# ESP32 register map
Vendor: ESPRESSIF SYSTEMS (SHANGHAI) CO., LTD.; Series: ESP32 Series; File version: 17
CPU: Xtensa LX6 r0p0, little endian, no MPU, FPU, 0 interrupt priority bits
Address unit: 32 bits
Registers are 32-bit, read-write, reset 0x0 unless marked. A register's access mark holds for its fields unless they carry their own. Offsets are from the block's base; [hi:lo] are bit positions; {n}, {i} and the like mark numbered series.

## RMT — Remote Control
Base 0x3FF56000
{0x0+4i} CH{i}DATA (i=0..7) access not given
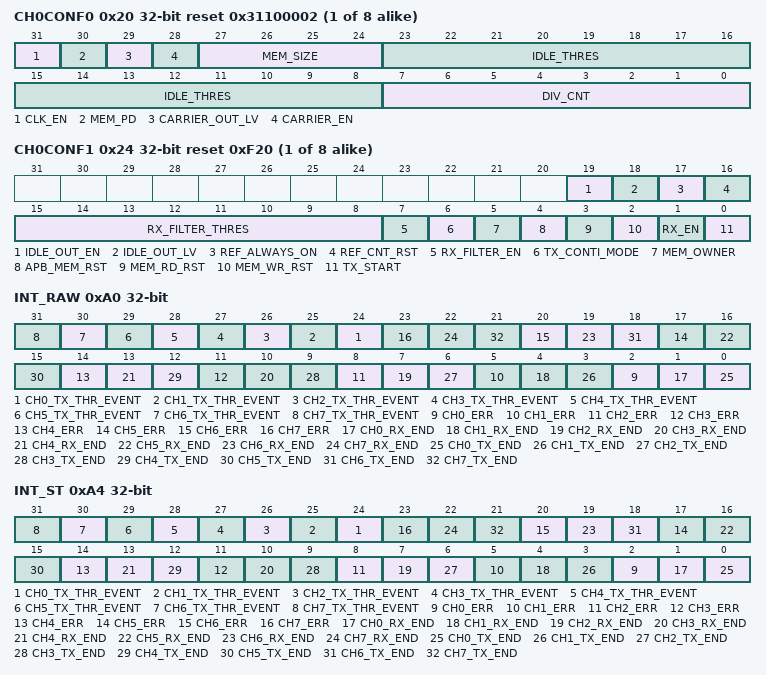
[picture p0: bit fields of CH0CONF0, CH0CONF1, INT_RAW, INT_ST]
{0x20+8i} CH{i}CONF0 (i=0..7) reset 0x31100002
  [31] CLK_EN — This bit is used to control clock.when software config RMT internal registers it controls the register clock.
  [30] MEM_PD — This bit is used to reduce power consumed by mem. 1:mem is in low power state.
  [29] CARRIER_OUT_LV — This bit is used to configure the way carrier wave is modulated for channel0.1'b1:transmit on low output level 1'b0:transmit on high output level.
  [28] CARRIER_EN — This is the carrier modulation enable control bit for channel0.
  [27:24] MEM_SIZE — This register is used to configure the the amount of memory blocks allocated to channel0.
  [23:8] IDLE_THRES — In receive mode when no edge is detected on the input signal for longer than reg_idle_thres_ch0 then the receive process is done.
  [7:0] DIV_CNT — This register is used to configure the frequency divider's factor in channel0.
{0x24+8i} CH{i}CONF1 (i=0..7) reset 0xF20
  [19] IDLE_OUT_EN — This is the output enable control bit for channel0 in IDLE state.
  [18] IDLE_OUT_LV — This bit configures the output signal's level for channel0 in IDLE state.
  [17] REF_ALWAYS_ON — This bit is used to select base clock. 1'b1:clk_apb 1'b0:clk_ref
  [16] REF_CNT_RST — This bit is used to reset divider in channel0.
  [15:8] RX_FILTER_THRES — in receive mode channel0 ignore input pulse when the pulse width is smaller then this value.
  [7] RX_FILTER_EN — This is the receive filter enable bit for channel0.
  [6] TX_CONTI_MODE — Set this bit to continue sending from the first data to the last data in channel0 again and again.
  [5] MEM_OWNER — This is the mark of channel0's ram usage right.1'b1：receiver uses the ram 0：transmitter uses the ram
  [4] APB_MEM_RST — Set this bit to reset W/R ram address for channel0 by apb fifo access
  [3] MEM_RD_RST — Set this bit to reset read ram address for channel0 by transmitter access.
  [2] MEM_WR_RST — Set this bit to reset write ram address for channel0 by receiver access.
  [1] RX_EN — Set this bit to enbale receving data for channel0.
  [0] TX_START — Set this bit to start sending data for channel0.
{0x60+4i} CH{i}STATUS (i=0..7) ro
  [31] APB_MEM_RD_ERR — The apb read memory status bit for channel0 turns to high level when the apb read address exceeds the configuration range.
  [30] APB_MEM_WR_ERR — The apb write memory status bit for channel0 turns to high level when the apb write address exceeds the configuration range.
  [29] MEM_EMPTY — The memory empty status bit for channel0. in acyclic mode, this bit turns to high level when mem_raddr_ex is greater than or equal to the configured range.
  [28] MEM_FULL — The memory full status bit for channel0 turns to high level when mem_waddr_ex is greater than or equal to the configuration range.
  [27] MEM_OWNER_ERR — When channel0 is configured for receive mode, this bit will turn to high level if rmt_mem_owner register is not set to 1.
  [26:24] STATE — The channel0 state machine status register.3'h0 : idle, 3'h1 : send, 3'h2 : read memory, 3'h3 : receive, 3'h4 : wait.
  [21:12] MEM_RADDR_EX — The current memory write address of channel0.
  [31:0] STATUS — The status for channel0
  [9:0] MEM_WADDR_EX — The current memory read address of channel0.
{0x80+4i} CH{i}ADDR (i=0..7) ro
  [31:0] APB_MEM_ADDR — The ram relative address in channel0 by apb fifo access
0xA0 INT_RAW ro
  [n+24] CH{n}_TX_THR_EVENT (n=0..7) — todo
  [3n+2] CH{n}_ERR (n=0..7) — todo
  [3n+1] CH{n}_RX_END (n=0..7) — The interrupt raw bit for channel {n} turns to high level when the receive process is done.
  [3n] CH{n}_TX_END (n=0..7) — The interrupt raw bit for channel {n} turns to high level when the transmit process is done.
0xA4 INT_ST ro
  [n+24] CH{n}_TX_THR_EVENT (n=0..7) — todo
  [3n+2] CH{n}_ERR (n=0..7) — todo
  [3n+1] CH{n}_RX_END (n=0..7) — todo
  [3n] CH{n}_TX_END (n=0..7) — todo
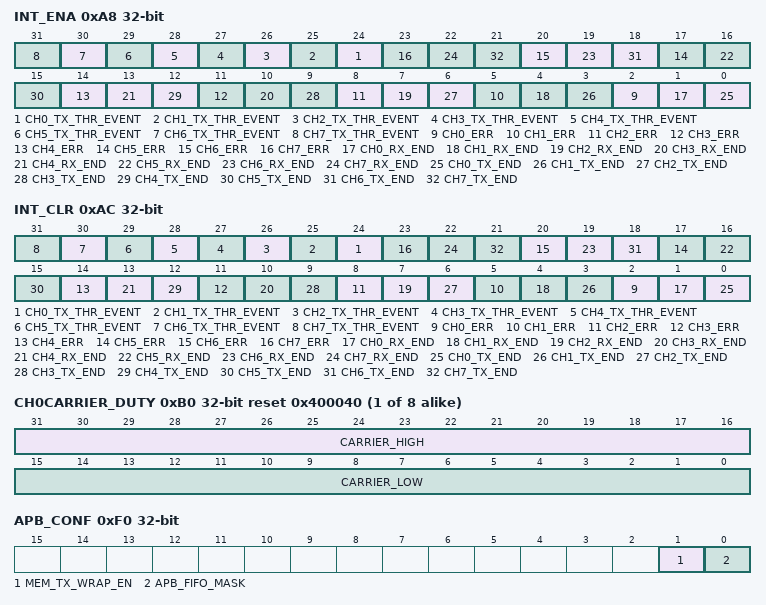
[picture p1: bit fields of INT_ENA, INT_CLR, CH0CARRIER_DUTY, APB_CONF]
0xA8 INT_ENA
  [n+24] CH{n}_TX_THR_EVENT (n=0..7) — Set this bit to enable rmt_ch{n}_tx_thr_event_int_st.
  [3n+2] CH{n}_ERR (n=0..7) — Set this bit to enable rmt_ch{n}_err_int_st.
  [3n+1] CH{n}_RX_END (n=0..7) — Set this bit to enable rmt_ch{n}_rx_end_int_st.
  [3n] CH{n}_TX_END (n=0..7) — Set this bit to enable rmt_ch{n}_tx_end_int_st.
0xAC INT_CLR wo
  [n+24] CH{n}_TX_THR_EVENT (n=0..7) — Set this bit to clear the rmt_ch{n}_tx_thr_event_int_raw interrupt.
  [3n+2] CH{n}_ERR (n=0..7) — Set this bit to clear the rmt_ch{n}_err_int_raw.
  [3n+1] CH{n}_RX_END (n=0..7) — Set this bit to clear the rmt_ch{n}_tx_end_int_raw.
  [3n] CH{n}_TX_END (n=0..7) — Set this bit to clear the rmt_ch{n}_rx_end_int_raw..
{0xB0+4i} CH{i}CARRIER_DUTY (i=0..7) reset 0x400040
  [31:16] CARRIER_HIGH — This register is used to configure carrier wave's high level value for channel0.
  [15:0] CARRIER_LOW — This register is used to configure carrier wave's low level value for channel0.
{0xD0+4i} CH{i}_TX_LIM (i=0..7) reset 0x80
  [8:0] TX_LIM — When channel0 sends more than reg_rmt_tx_lim_ch0 datas then channel0 produce the relative interrupt.
0xF0 APB_CONF
  [1] MEM_TX_WRAP_EN — when datas need to be send is more than channel's mem can store then set this bit to enable reusage of mem this bit is used together with reg_rmt_tx_lim_chn.
  [0] APB_FIFO_MASK — Set this bit to disable apb fifo access
0xFC DATE
